# SWM190 register map
File version: 1.0
CPU: CM0 r1p0, little endian, 2 interrupt priority bits
Registers are 32-bit, read-write, no defined reset value unless marked. A register's access mark holds for its fields unless they carry their own. Offsets are from the block's base; [hi:lo] are bit positions; lines under a group give offsets from that group; {n}, {i} and the like mark numbered series; 'fields as' and 'values as' point back to an identical list.

## ADC0 — Registers group
Base 0x40049000
Same registers: ADC1 0x40049800
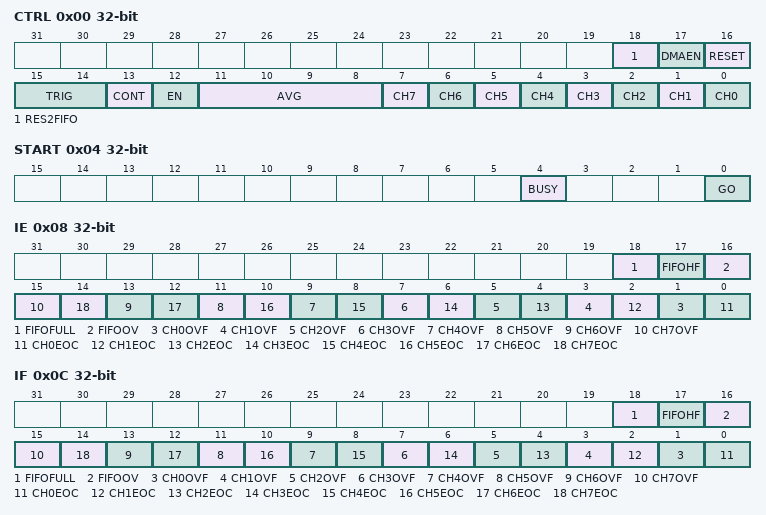
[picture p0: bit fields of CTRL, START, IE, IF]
0x00 CTRL
  [18] RES2FIFO, [17] DMAEN, [16] RESET, [15:14] TRIG, [13] CONT, [12] EN, [11:8] AVG, [n] CH{n} (n=0..7)
0x04 START
  [4] BUSY, [0] GO
0x08 IE
  [18] FIFOFULL, [17] FIFOHF, [16] FIFOOV, [2n+1] CH{n}OVF (n=0..7), [2n] CH{n}EOC (n=0..7)
0x0C IF
  fields as IE
{0x10+0x10*i} CH{i} group (i=0..7) — register cluster
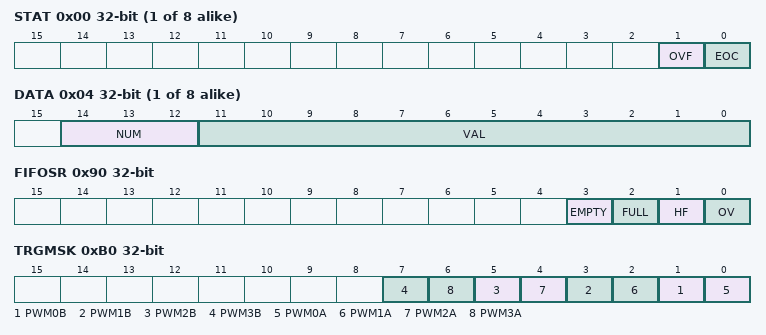
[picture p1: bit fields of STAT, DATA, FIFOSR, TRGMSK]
  0x00 STAT
    [1] OVF, [0] EOC
  0x04 DATA
    [14:12] NUM, [11:0] VAL
0x90 FIFOSR
  [3] EMPTY, [2] FULL, [1] HF, [0] OV
0x94 FIFODR
0xB0 TRGMSK
  [2n+1] PWM{n}B (n=0..3), [2n] PWM{n}A (n=0..3)

## PWM0 — Registers group
Base 0x40046000
Same registers: PWM1 0x40046040, PWM2 0x40046080, PWM3 0x400460C0
0x00 MODE
0x04 PERA
0x08 HIGHA
0x0C DZA
0x10 PERB
0x14 HIGHB
0x18 DZB
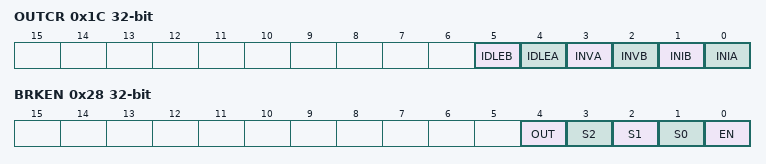
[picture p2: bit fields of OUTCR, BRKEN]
0x1C OUTCR
  [5] IDLEB, [4] IDLEA, [3] INVA, [2] INVB, [1] INIB, [0] INIA
0x20 ADTRGA0
0x24 ADTRGA1
0x28 BRKEN
  [4] OUT, [3] S2, [2] S1, [1] S0, [0] EN
0x2C VALUEA
0x30 VALUEB
0x34 ADTRGB0
0x38 ADTRGB1

## PWMG — Registers group
Base 0x40046200
0x00 CLKDIV
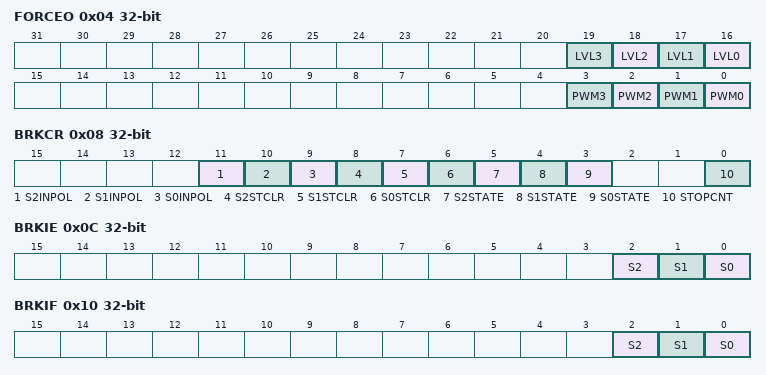
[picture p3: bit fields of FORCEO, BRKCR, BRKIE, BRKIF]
0x04 FORCEO
  [n+16] LVL{n} (n=0..3), [n] PWM{n} (n=0..3)
0x08 BRKCR
  [11] S2INPOL, [10] S1INPOL, [9] S0INPOL, [8] S2STCLR, [7] S1STCLR, [6] S0STCLR, [5] S2STATE, [4] S1STATE, [3] S0STATE, [0] STOPCNT
0x0C BRKIE
  [2] S2, [1] S1, [0] S0
0x10 BRKIF ro
  [2] S2, [1] S1, [0] S0
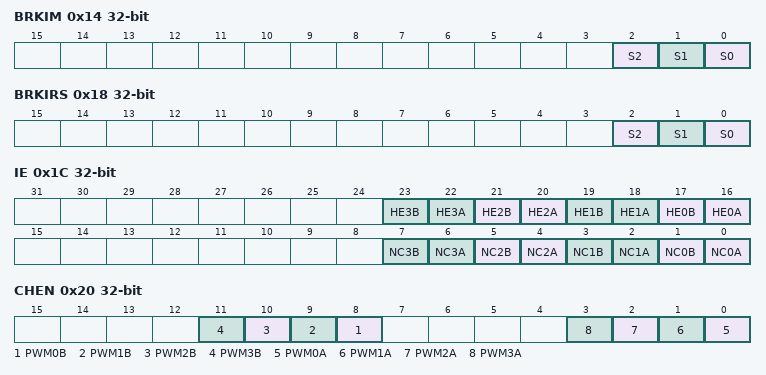
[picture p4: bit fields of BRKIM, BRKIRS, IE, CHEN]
0x14 BRKIM
  [2] S2, [1] S1, [0] S0
0x18 BRKIRS
  [2] S2, [1] S1, [0] S0
0x1C IE
  [2n+17] HE{n}B (n=0..3), [2n+16] HE{n}A (n=0..3), [2n+1] NC{n}B (n=0..3), [2n] NC{n}A (n=0..3)
0x20 CHEN
  [n+8] PWM{n}B (n=0..3), [n] PWM{n}A (n=0..3)
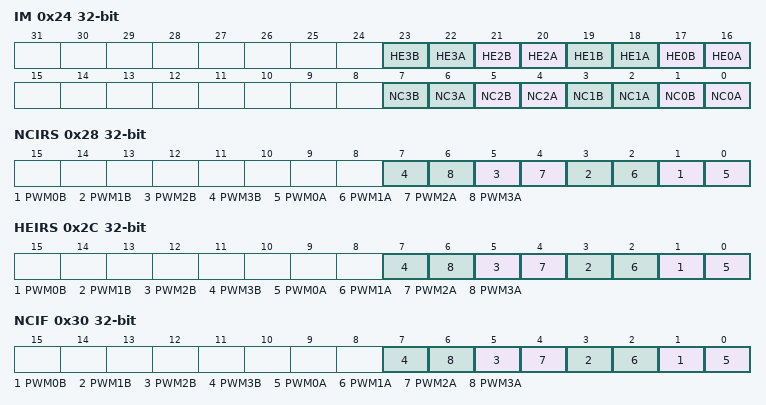
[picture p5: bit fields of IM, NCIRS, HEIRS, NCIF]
0x24 IM
  fields as IE
0x28 NCIRS
  [2n+1] PWM{n}B (n=0..3), [2n] PWM{n}A (n=0..3)
0x2C HEIRS
  [2n+1] PWM{n}B (n=0..3), [2n] PWM{n}A (n=0..3)
0x30 NCIF ro
  [2n+1] PWM{n}B (n=0..3), [2n] PWM{n}A (n=0..3)
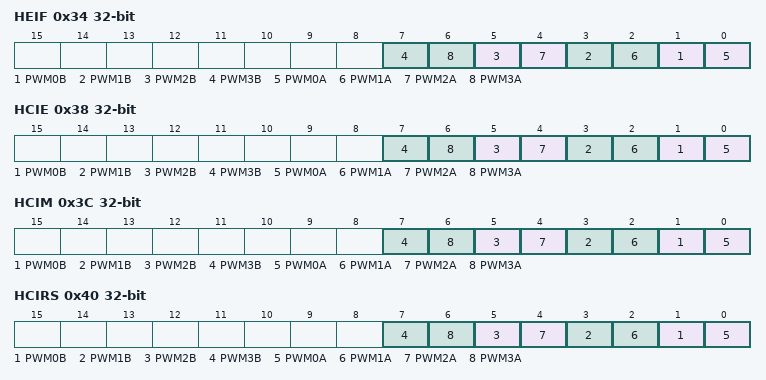
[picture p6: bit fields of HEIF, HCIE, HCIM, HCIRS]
0x34 HEIF ro
  [2n+1] PWM{n}B (n=0..3), [2n] PWM{n}A (n=0..3)
0x38 HCIE
  [2n+1] PWM{n}B (n=0..3), [2n] PWM{n}A (n=0..3)
0x3C HCIM
  [2n+1] PWM{n}B (n=0..3), [2n] PWM{n}A (n=0..3)
0x40 HCIRS
  [2n+1] PWM{n}B (n=0..3), [2n] PWM{n}A (n=0..3)
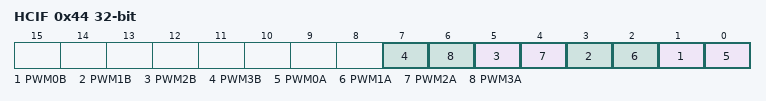
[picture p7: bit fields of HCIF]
0x44 HCIF ro
  [2n+1] PWM{n}B (n=0..3), [2n] PWM{n}A (n=0..3)

## DMA — Registers group
Base 0x40000800
0x00 EN
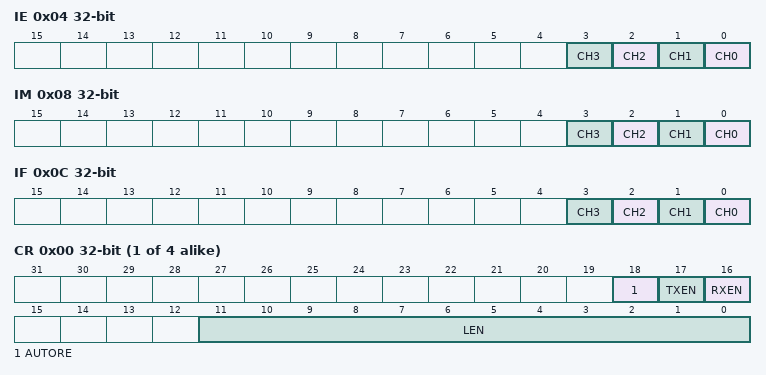
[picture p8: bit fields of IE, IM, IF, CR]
0x04 IE
  [n] CH{n} (n=0..3)
0x08 IM
  [n] CH{n} (n=0..3)
0x0C IF
  [n] CH{n} (n=0..3)
0x10 DSTSGIE
0x14 DSTSGIM
0x18 DSTSGIF
0x1C SRCSGIE
0x20 SRCSGIM
0x24 SRCSGIF
0x3C PRI
{0x40+0x40*i} CH{i} group (i=0..3) — register cluster
  0x00 CR
    [18] AUTORE, [17] TXEN, [16] RXEN, [11:0] LEN
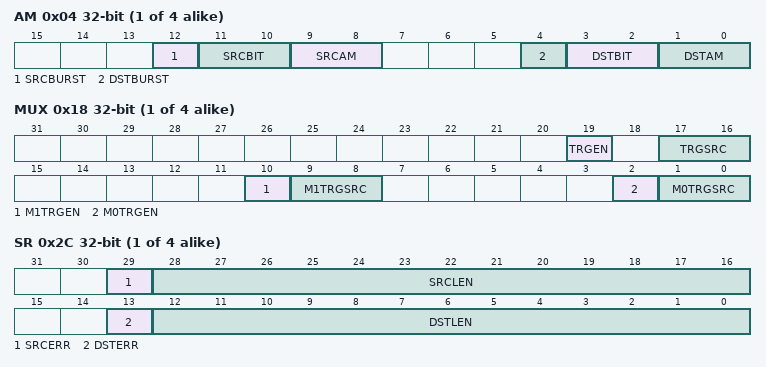
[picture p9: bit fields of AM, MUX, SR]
  0x04 AM
    [12] SRCBURST, [11:10] SRCBIT, [9:8] SRCAM, [4] DSTBURST, [3:2] DSTBIT, [1:0] DSTAM
  0x08 DST
  {0x8+4j} DSTSGADDR{j} (j=1..3)
  0x18 MUX
    [19] TRGEN, [17:16] TRGSRC, [10] M1TRGEN, [9:8] M1TRGSRC, [2] M0TRGEN, [1:0] M0TRGSRC
  0x1C SRC
  {0x1C+4j} SRCSGADDR{j} (j=1..3)
  0x2C SR ro
    [29] SRCERR, [28:16] SRCLEN, [13] DSTERR, [12:0] DSTLEN

## DIV — Registers group
Base 0x40003800
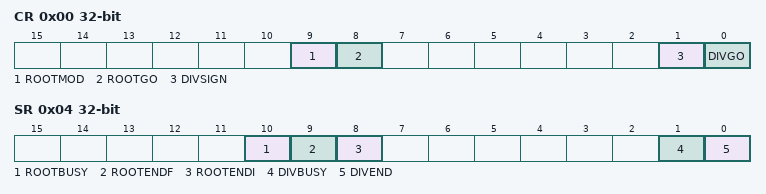
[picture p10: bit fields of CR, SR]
0x00 CR
  [9] ROOTMOD, [8] ROOTGO, [1] DIVSIGN, [0] DIVGO
0x04 SR
  [10] ROOTBUSY, [9] ROOTENDF, [8] ROOTENDI, [1] DIVBUSY, [0] DIVEND
0x10 DIVIDEND
0x14 DIVISOR
0x18 QUO
0x1C REMAIN
0x20 RADICAND
0x24 ROOT

## CORDIC — Registers group
Base 0x40003000
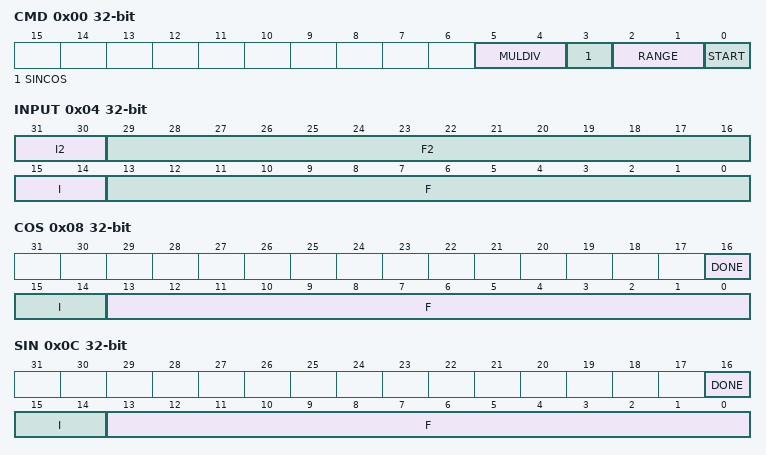
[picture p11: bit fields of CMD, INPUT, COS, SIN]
0x00 CMD
  [5:4] MULDIV, [3] SINCOS, [2:1] RANGE, [0] START
0x04 INPUT
  [31:30] I2, [29:16] F2, [15:14] I, [13:0] F
0x08 COS
  [16] DONE, [15:14] I, [13:0] F
0x0C SIN
  [16] DONE, [15:14] I, [13:0] F
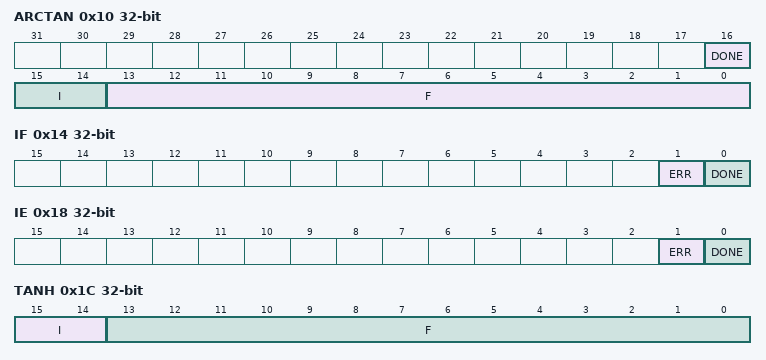
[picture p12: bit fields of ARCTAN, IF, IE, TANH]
0x10 ARCTAN
  [16] DONE, [15:14] I, [13:0] F
0x14 IF
  [1] ERR, [0] DONE
0x18 IE
  [1] ERR, [0] DONE
0x1C TANH
  [15:14] I, [13:0] F

## CACHE — Registers group
Base 0x40005800
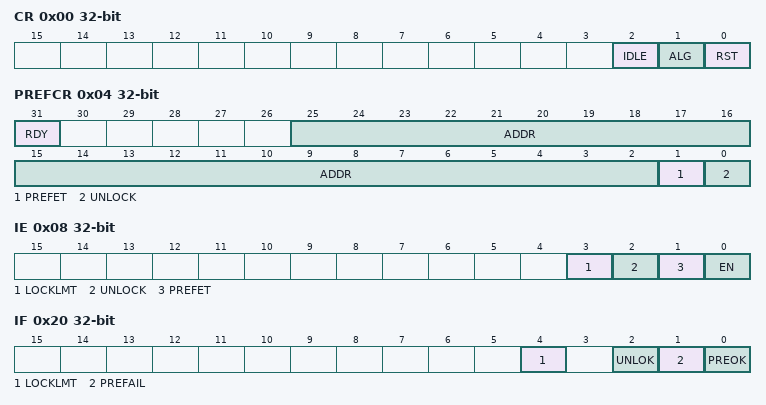
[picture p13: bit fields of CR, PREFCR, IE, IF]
0x00 CR
  [2] IDLE, [1] ALG, [0] RST
0x04 PREFCR
  [31] RDY, [25:2] ADDR, [1] PREFET, [0] UNLOCK
0x08 IE
  [3] LOCKLMT, [2] UNLOCK, [1] PREFET, [0] EN
0x0C LOCKLMT
0x10 LOCKCNT ro
0x14 CURLINE ro
0x18 ACCESSCNT ro
0x1C HITCNT ro
0x20 IF
  [4] LOCKLMT, [2] UNLOK, [1] PREFAIL, [0] PREOK

## SFC — Registers group
Base 0x4004A000
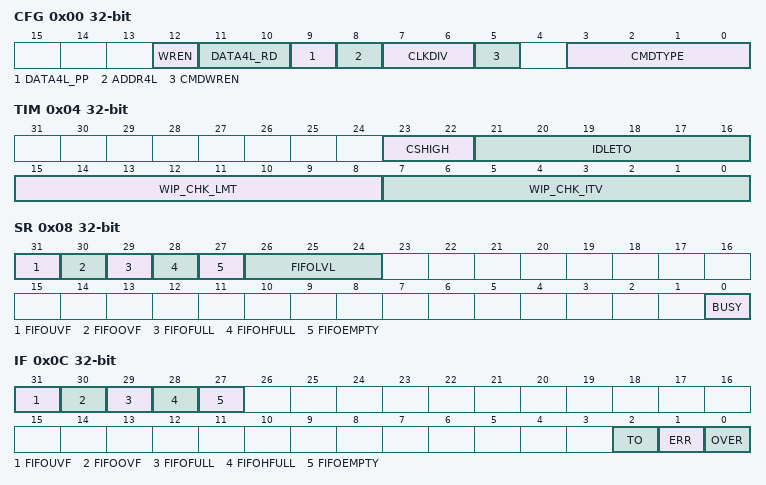
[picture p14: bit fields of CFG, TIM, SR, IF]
0x00 CFG
  [12] WREN, [11:10] DATA4L_RD, [9] DATA4L_PP, [8] ADDR4L, [7:6] CLKDIV, [5] CMDWREN, [3:0] CMDTYPE
0x04 TIM
  [23:22] CSHIGH, [21:16] IDLETO, [15:8] WIP_CHK_LMT, [7:0] WIP_CHK_ITV
0x08 SR ro
  [31] FIFOUVF, [30] FIFOOVF, [29] FIFOFULL, [28] FIFOHFULL, [27] FIFOEMPTY, [26:24] FIFOLVL, [0] BUSY
0x0C IF
  [31] FIFOUVF, [30] FIFOOVF, [29] FIFOFULL, [28] FIFOHFULL, [27] FIFOEMPTY, [2] TO, [1] ERR, [0] OVER
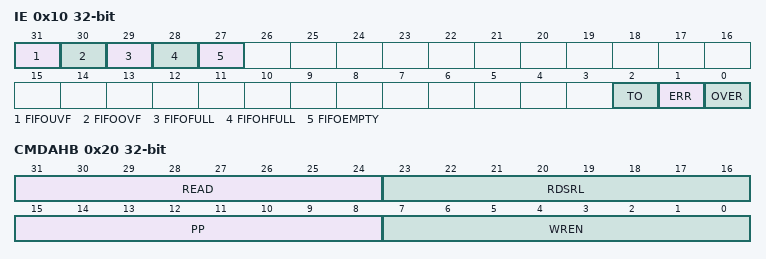
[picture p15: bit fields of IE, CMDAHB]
0x10 IE
  fields as IF
0x14 GO
0x18 ADDR
0x1C DATA
0x20 CMDAHB
  [31:24] READ, [23:16] RDSRL, [15:8] PP, [7:0] WREN
0x24 CMD

## RTC — Registers group
Base 0x4004B800
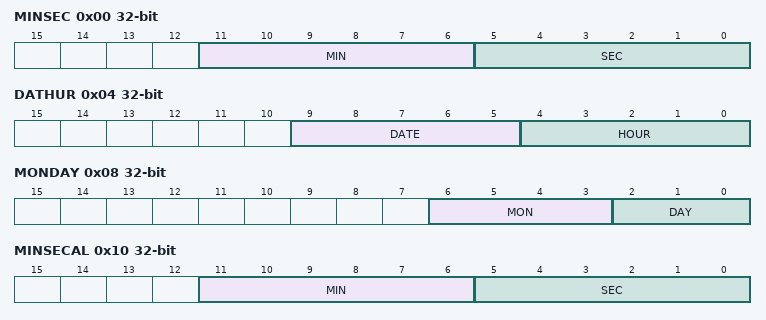
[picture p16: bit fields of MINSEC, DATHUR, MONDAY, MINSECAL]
0x00 MINSEC
  [11:6] MIN, [5:0] SEC
0x04 DATHUR
  [9:5] DATE, [4:0] HOUR
0x08 MONDAY
  [6:3] MON, [2:0] DAY
0x0C YEAR
0x10 MINSECAL
  [11:6] MIN, [5:0] SEC
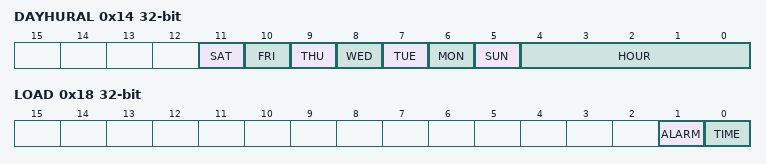
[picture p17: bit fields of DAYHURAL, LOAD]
0x14 DAYHURAL
  [11] SAT, [10] FRI, [9] THU, [8] WED, [7] TUE, [6] MON, [5] SUN, [4:0] HOUR
0x18 LOAD
  [1] ALARM, [0] TIME
0x1C IE
  [4] ALARM, [3] DATE, [2] HOUR, [1] MIN, [0] SEC
0x20 IF
  [4] ALARM, [3] DATE, [2] HOUR, [1] MIN, [0] SEC
0x24 EN
0x28 CFGABLE
0x2C TRIM
  [8] DEC, [7:0] ADJ
0x30 TRIMM
  [3] INC, [2:0] CYCLE

## WDT — Registers group
Base 0x400A0800
0x00 RSTVAL
0x04 INTVAL
0x08 CR
  [2] INTEN, [1] RSTEN, [0] EN
0x0C IF
0x10 FEED
